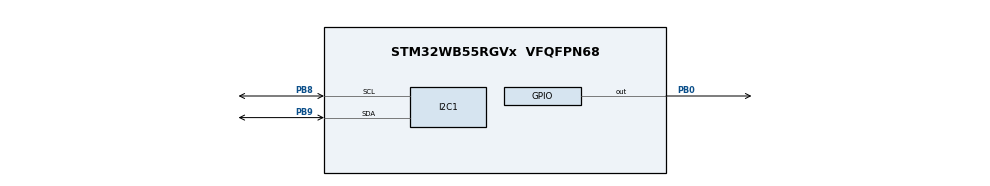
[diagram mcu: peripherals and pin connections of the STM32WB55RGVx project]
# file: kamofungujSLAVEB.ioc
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Dma.I2C1_RX.1.Direction=DMA_PERIPH_TO_MEMORY
Dma.I2C1_RX.1.EventEnable=DISABLE
Dma.I2C1_RX.1.Instance=DMA1_Channel2
Dma.I2C1_RX.1.MemDataAlignment=DMA_MDATAALIGN_BYTE
Dma.I2C1_RX.1.MemInc=DMA_MINC_ENABLE
Dma.I2C1_RX.1.Mode=DMA_NORMAL
Dma.I2C1_RX.1.PeriphDataAlignment=DMA_PDATAALIGN_BYTE
Dma.I2C1_RX.1.PeriphInc=DMA_PINC_DISABLE
Dma.I2C1_RX.1.Polarity=HAL_DMAMUX_REQ_GEN_RISING
Dma.I2C1_RX.1.Priority=DMA_PRIORITY_LOW
Dma.I2C1_RX.1.RequestNumber=1
Dma.I2C1_RX.1.SignalID=NONE
Dma.I2C1_RX.1.SyncEnable=DISABLE
Dma.I2C1_RX.1.SyncPolarity=HAL_DMAMUX_SYNC_NO_EVENT
Dma.I2C1_RX.1.SyncRequestNumber=1
Dma.I2C1_RX.1.SyncSignalID=NONE
Dma.I2C1_TX.0.Direction=DMA_MEMORY_TO_PERIPH
Dma.I2C1_TX.0.EventEnable=DISABLE
Dma.I2C1_TX.0.Instance=DMA1_Channel1
Dma.I2C1_TX.0.MemDataAlignment=DMA_MDATAALIGN_BYTE
Dma.I2C1_TX.0.MemInc=DMA_MINC_ENABLE
Dma.I2C1_TX.0.Mode=DMA_NORMAL
Dma.I2C1_TX.0.PeriphDataAlignment=DMA_PDATAALIGN_BYTE
Dma.I2C1_TX.0.PeriphInc=DMA_PINC_DISABLE
Dma.I2C1_TX.0.Polarity=HAL_DMAMUX_REQ_GEN_RISING
Dma.I2C1_TX.0.Priority=DMA_PRIORITY_LOW
Dma.I2C1_TX.0.RequestNumber=1
Dma.I2C1_TX.0.SignalID=NONE
Dma.I2C1_TX.0.SyncEnable=DISABLE
Dma.I2C1_TX.0.SyncPolarity=HAL_DMAMUX_SYNC_NO_EVENT
Dma.I2C1_TX.0.SyncRequestNumber=1
Dma.I2C1_TX.0.SyncSignalID=NONE
Dma.Request0=I2C1_TX
Dma.Request1=I2C1_RX
I2C1.OwnAddress=0x14
I2C1.Timing=0x00100D14
Mcu.Family=STM32WB
Mcu.Name=STM32WB55RGVx
Mcu.Package=VFQFPN68
NVIC.DMA1_Channel1_IRQn=true\:0\:0\:false\:false\:true\:false\:true\:true
NVIC.DMA1_Channel2_IRQn=true\:0\:0\:false\:false\:true\:false\:true\:true
NVIC.I2C1_ER_IRQn=true\:0\:0\:false\:false\:true\:true\:true\:true
NVIC.I2C1_EV_IRQn=true\:0\:0\:false\:false\:true\:true\:true\:true
NVIC.PriorityGroup=NVIC_PRIORITYGROUP_4
PB0.Signal=GPIO_Output
PB8.GPIO_Pu=GPIO_PULLUP
PB8.GPIO_Speed=GPIO_SPEED_FREQ_VERY_HIGH
PB8.Mode=I2C
PB8.Signal=I2C1_SCL
PB9.GPIO_Pu=GPIO_PULLUP
PB9.GPIO_Speed=GPIO_SPEED_FREQ_VERY_HIGH
PB9.Mode=I2C
PB9.Signal=I2C1_SDA
ProjectManager.HeapSize=0x200
ProjectManager.StackSize=0x400
ProjectManager.TargetToolchain=STM32CubeIDE
RCC.APB3Freq_Value=16000000
RCC.HSE_VALUE=8000000
RCC.HSI48_VALUE=48000000
RCC.HSI_VALUE=16000000
RCC.LSE_VALUE=32768
RCC.VCOOutputFreq_Value=32000000
VP_MEMORYMAP_VS_MEMORYMAP.Mode=CurAppReg
board=custom

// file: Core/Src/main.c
/* USER CODE BEGIN Header */
/**
  ******************************************************************************
  * @file           : main.c
  * @brief          : Main program body
  ******************************************************************************
  * @attention
  *
  * Copyright (c) 2026 STMicroelectronics.
  * All rights reserved.
  *
  * This software is licensed under terms that can be found in the LICENSE file
  * in the root directory of this software component.
  * If no LICENSE file comes with this software, it is provided AS-IS.
  *
  ******************************************************************************
  */
/* USER CODE END Header */
#include "main.h"

I2C_HandleTypeDef hi2c1;
DMA_HandleTypeDef hdma_i2c1_tx;
DMA_HandleTypeDef hdma_i2c1_rx;

/* USER CODE BEGIN PV */

uint8_t RX_Buffer[1];
/* USER CODE END PV */

void SystemClock_Config(void);
void PeriphCommonClock_Config(void);
static void MX_GPIO_Init(void);
static void MX_DMA_Init(void);
static void MX_I2C1_Init(void);

int main(void)
{

  /* MCU Configuration--------------------------------------------------------*/

  /* Reset of all peripherals, Initializes the Flash interface and the Systick. */
  HAL_Init();

  /* Configure the system clock */
  SystemClock_Config();

  /* Configure the peripherals common clocks */
  PeriphCommonClock_Config();

  /* Initialize all configured peripherals */
  MX_GPIO_Init();
  MX_DMA_Init();
  MX_I2C1_Init();
  /* USER CODE BEGIN 2 */

    // PB9 - I2C1_SDA

  /* USER CODE END 2 */

  /* Infinite loop */
  /* USER CODE BEGIN WHILE */
  while (1)
  {
	  HAL_I2C_Slave_Receive(&hi2c1,
	                              RX_Buffer,
	                              1,
	                              1000);
	        HAL_Delay(100);

	        HAL_StatusTypeDef ret;

	        ret = HAL_I2C_Slave_Receive(&hi2c1, RX_Buffer, 1, 1000);

	        uint32_t err = HAL_I2C_GetError(&hi2c1);
	   if (ret == HAL_OK)
	      {
	                // sem daj breakpoint
	                // alebo toggle LED
	        HAL_GPIO_TogglePin(GPIOB, GPIO_PIN_0);
	        }
    /* USER CODE END WHILE */

  }
}

void SystemClock_Config(void)
{
  RCC_OscInitTypeDef RCC_OscInitStruct = {0};
  RCC_ClkInitTypeDef RCC_ClkInitStruct = {0};

  /** Configure the main internal regulator output voltage
  */
  __HAL_PWR_VOLTAGESCALING_CONFIG(PWR_REGULATOR_VOLTAGE_SCALE1);

  /** Initializes the RCC Oscillators according to the specified parameters
  * in the RCC_OscInitTypeDef structure.
  */
  RCC_OscInitStruct.OscillatorType = RCC_OSCILLATORTYPE_HSI|RCC_OSCILLATORTYPE_MSI;
  RCC_OscInitStruct.HSIState = RCC_HSI_ON;
  RCC_OscInitStruct.MSIState = RCC_MSI_ON;
  RCC_OscInitStruct.HSICalibrationValue = RCC_HSICALIBRATION_DEFAULT;
  RCC_OscInitStruct.MSICalibrationValue = RCC_MSICALIBRATION_DEFAULT;
  RCC_OscInitStruct.MSIClockRange = RCC_MSIRANGE_6;
  RCC_OscInitStruct.PLL.PLLState = RCC_PLL_NONE;
  if (HAL_RCC_OscConfig(&RCC_OscInitStruct) != HAL_OK)
  {
    Error_Handler();
  }

  /** Configure the SYSCLKSource, HCLK, PCLK1 and PCLK2 clocks dividers
  */
  RCC_ClkInitStruct.ClockType = RCC_CLOCKTYPE_HCLK4|RCC_CLOCKTYPE_HCLK2
                              |RCC_CLOCKTYPE_HCLK|RCC_CLOCKTYPE_SYSCLK
                              |RCC_CLOCKTYPE_PCLK1|RCC_CLOCKTYPE_PCLK2;
  RCC_ClkInitStruct.SYSCLKSource = RCC_SYSCLKSOURCE_MSI;
  RCC_ClkInitStruct.AHBCLKDivider = RCC_SYSCLK_DIV1;
  RCC_ClkInitStruct.APB1CLKDivider = RCC_HCLK_DIV1;
  RCC_ClkInitStruct.APB2CLKDivider = RCC_HCLK_DIV1;
  RCC_ClkInitStruct.AHBCLK2Divider = RCC_SYSCLK_DIV1;
  RCC_ClkInitStruct.AHBCLK4Divider = RCC_SYSCLK_DIV1;

  if (HAL_RCC_ClockConfig(&RCC_ClkInitStruct, FLASH_LATENCY_0) != HAL_OK)
  {
    Error_Handler();
  }
}

void PeriphCommonClock_Config(void)
{
  RCC_PeriphCLKInitTypeDef PeriphClkInitStruct = {0};

  /** Initializes the peripherals clock
  */
  PeriphClkInitStruct.PeriphClockSelection = RCC_PERIPHCLK_SMPS;
  PeriphClkInitStruct.SmpsClockSelection = RCC_SMPSCLKSOURCE_HSI;
  PeriphClkInitStruct.SmpsDivSelection = RCC_SMPSCLKDIV_RANGE1;

  if (HAL_RCCEx_PeriphCLKConfig(&PeriphClkInitStruct) != HAL_OK)
  {
    Error_Handler();
  }
}

static void MX_I2C1_Init(void)
{

  hi2c1.Instance = I2C1;
  hi2c1.Init.Timing = 0x00100D14;
  hi2c1.Init.OwnAddress1 = 40;
  hi2c1.Init.AddressingMode = I2C_ADDRESSINGMODE_7BIT;
  hi2c1.Init.DualAddressMode = I2C_DUALADDRESS_DISABLE;
  hi2c1.Init.OwnAddress2 = 0;
  hi2c1.Init.OwnAddress2Masks = I2C_OA2_NOMASK;
  hi2c1.Init.GeneralCallMode = I2C_GENERALCALL_DISABLE;
  hi2c1.Init.NoStretchMode = I2C_NOSTRETCH_DISABLE;
  if (HAL_I2C_Init(&hi2c1) != HAL_OK)
  {
    Error_Handler();
  }

  /** Configure Analogue filter
  */
  if (HAL_I2CEx_ConfigAnalogFilter(&hi2c1, I2C_ANALOGFILTER_ENABLE) != HAL_OK)
  {
    Error_Handler();
  }

  /** Configure Digital filter
  */
  if (HAL_I2CEx_ConfigDigitalFilter(&hi2c1, 0) != HAL_OK)
  {
    Error_Handler();
  }

}

static void MX_DMA_Init(void)
{

  /* DMA controller clock enable */
  __HAL_RCC_DMAMUX1_CLK_ENABLE();
  __HAL_RCC_DMA1_CLK_ENABLE();

  /* DMA interrupt init */
  /* DMA1_Channel1_IRQn interrupt configuration */
  HAL_NVIC_SetPriority(DMA1_Channel1_IRQn, 0, 0);
  HAL_NVIC_EnableIRQ(DMA1_Channel1_IRQn);
  /* DMA1_Channel2_IRQn interrupt configuration */
  HAL_NVIC_SetPriority(DMA1_Channel2_IRQn, 0, 0);
  HAL_NVIC_EnableIRQ(DMA1_Channel2_IRQn);

}

static void MX_GPIO_Init(void)
{
  GPIO_InitTypeDef GPIO_InitStruct = {0};

  /* GPIO Ports Clock Enable */
  __HAL_RCC_GPIOB_CLK_ENABLE();

  /*Configure GPIO pin Output Level */
  HAL_GPIO_WritePin(GPIOB, GPIO_PIN_0, GPIO_PIN_RESET);

  /*Configure GPIO pin : PB0 */
  GPIO_InitStruct.Pin = GPIO_PIN_0;
  GPIO_InitStruct.Mode = GPIO_MODE_OUTPUT_PP;
  GPIO_InitStruct.Pull = GPIO_NOPULL;
  GPIO_InitStruct.Speed = GPIO_SPEED_FREQ_LOW;
  HAL_GPIO_Init(GPIOB, &GPIO_InitStruct);

}

void Error_Handler(void)
{
  __disable_irq();
  while (1)
  {
  }
}
